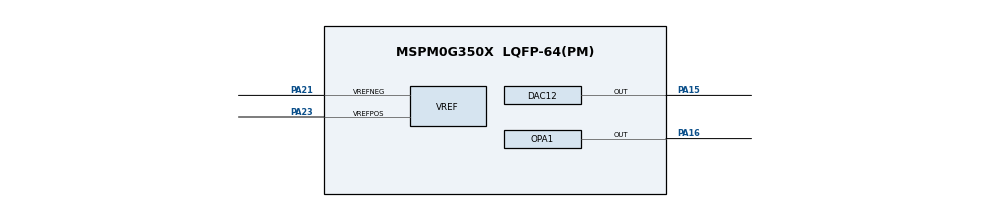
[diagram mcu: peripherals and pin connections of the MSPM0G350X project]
/**
 * @cliArgs --device "MSPM0G350X" --package "LQFP-64(PM)" --part "Default" --product "mspm0_sdk@2.01.00.03"
 * @versions {"tool":"1.19.0+3426"}
 */

/**
 * Import the modules used in this configuration.
 */
const Board  = scripting.addModule("/ti/driverlib/Board");
const DAC12  = scripting.addModule("/ti/driverlib/DAC12");
const OPA    = scripting.addModule("/ti/driverlib/OPA", {}, false);
const OPA1   = OPA.addInstance();
const SYSCTL = scripting.addModule("/ti/driverlib/SYSCTL");
const VREF   = scripting.addModule("/ti/driverlib/VREF");

/**
 * Write custom configuration values to the imported modules.
 */
const gate8  = system.clockTree["MFPCLKGATE"];
gate8.enable = true;

Board.InitPriority21 = "/ti/driverlib/OPA";

DAC12.dacPosVREF                = "VEREFP";
DAC12.dacNegVREF                = "VEREFN";
DAC12.dacOutputPinEn            = true;
DAC12.dacOutput12               = 2043;
DAC12.dacAmplifier              = "ON";
DAC12.peripheral.$assign        = "DAC0";
DAC12.peripheral.OutPin.$assign = "PA15";
DAC12.OutPinConfig.$name        = "ti_driverlib_gpio_GPIOPinGeneric1";

OPA1.$name                     = "OPA_0";
OPA1.cfg0NSELChannel           = "RTAP";
OPA1.cfg0OutputPin             = "ENABLED";
OPA1.advBW                     = "HIGH";
OPA1.cfg0MSELChannel           = "DAC_OUT";
OPA1.cfg0PSELChannel           = "IN1_POS";
OPA1.cfg0Gain                  = "N1_P2";
OPA1.peripheral.$assign        = "OPA1";
OPA1.peripheral.OutPin.$assign = "PA16";
OPA1.OutPinConfig.$name        = "ti_driverlib_gpio_GPIOPinGeneric3";
OPA1.In1PosPinConfig.$name     = "ti_driverlib_gpio_GPIOPinGeneric2";

SYSCTL.MFPCLKEn              = true;
SYSCTL.forceDefaultClkConfig = true;
SYSCTL.clockTreeEn           = true;

VREF.advClockConfigEnable          = true;
VREF.advClkSrc                     = "DL_VREF_CLOCK_BUSCLK";
VREF.basicIntVolt                  = "DL_VREF_BUFCONFIG_OUTPUT_2_5V";
VREF.checkVREFReady                = true;
VREF.basicVrefPins                 = "VREF+-";
VREF.peripheral.$assign            = "VREF";
VREF.peripheral.vrefPosPin.$assign = "PA23";
VREF.peripheral.vrefNegPin.$assign = "PA21";
VREF.vrefPosPinConfig.$name        = "ti_driverlib_gpio_GPIOPinGeneric0";
VREF.vrefNegPinConfig.$name        = "ti_driverlib_gpio_GPIOPinGeneric4";

/**
 * Pinmux solution for unlocked pins/peripherals. This ensures that minor changes to the automatic solver in a future
 * version of the tool will not impact the pinmux you originally saw.  These lines can be completely deleted in order to
 * re-solve from scratch.
 */
Board.peripheral.$suggestSolution          = "DEBUGSS";
Board.peripheral.swclkPin.$suggestSolution = "PA20";
Board.peripheral.swdioPin.$suggestSolution = "PA19";
OPA1.peripheral.In1PosPin.$suggestSolution = "PA18";
